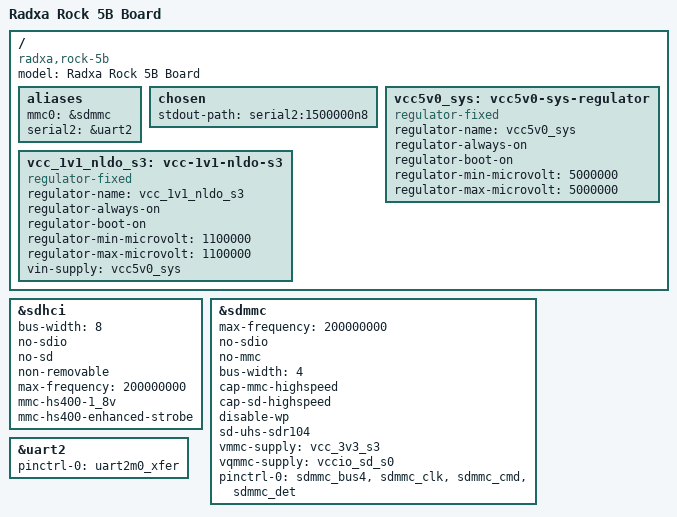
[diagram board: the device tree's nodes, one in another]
// SPDX-License-Identifier: (GPL-2.0+ OR MIT)

/dts-v1/;

#include "rk3588.dtsi"
#include "rk3588-rk806-single.dtsi"

/ {
	model = "Radxa Rock 5B Board";
	compatible = "radxa,rock-5b", "rockchip,rk3588";

	aliases {
		mmc0 = &sdmmc;
		//mmc1 = &sdhci;
		serial2 = &uart2;
	};

	chosen {
		stdout-path = "serial2:1500000n8";
	};

	vcc5v0_sys: vcc5v0-sys-regulator {
		compatible = "regulator-fixed";
		regulator-name = "vcc5v0_sys";
		regulator-always-on;
		regulator-boot-on;
		regulator-min-microvolt = <5000000>;
		regulator-max-microvolt = <5000000>;
	};

	vcc_1v1_nldo_s3: vcc-1v1-nldo-s3 {
		compatible = "regulator-fixed";
		regulator-name = "vcc_1v1_nldo_s3";
		regulator-always-on;
		regulator-boot-on;
		regulator-min-microvolt = <1100000>;
		regulator-max-microvolt = <1100000>;
		vin-supply = <&vcc5v0_sys>;
	};
};

&sdhci {
	bus-width = <8>;
	no-sdio;
	no-sd;
	non-removable;
	max-frequency = <200000000>;
	mmc-hs400-1_8v;
	mmc-hs400-enhanced-strobe;
	status = "okay";
};

&sdmmc {
	max-frequency = <200000000>;
	no-sdio;
	no-mmc;
	bus-width = <4>;
	cap-mmc-highspeed;
	cap-sd-highspeed;
	disable-wp;
	sd-uhs-sdr104;
	vmmc-supply = <&vcc_3v3_s3>;
	vqmmc-supply = <&vccio_sd_s0>;
	pinctrl-names = "default";
	pinctrl-0 = <&sdmmc_bus4 &sdmmc_clk &sdmmc_cmd &sdmmc_det>;
	status = "okay";
};

&uart2 {
	pinctrl-0 = <&uart2m0_xfer>;
	status = "okay";
};
